# QN908XC register map
Vendor: nxp.com; File version: 1.0
CPU: CM4 r0p1, little endian, no MPU, no FPU, 0x3 interrupt priority bits, 0x0 interrupts
Registers are 32-bit, read-write, reset 0x0 unless marked. A register's access mark holds for its fields unless they carry their own. Offsets are from the block's base; [hi:lo] are bit positions; {n}, {i} and the like mark numbered series.

## FSP
Base 0x40088000
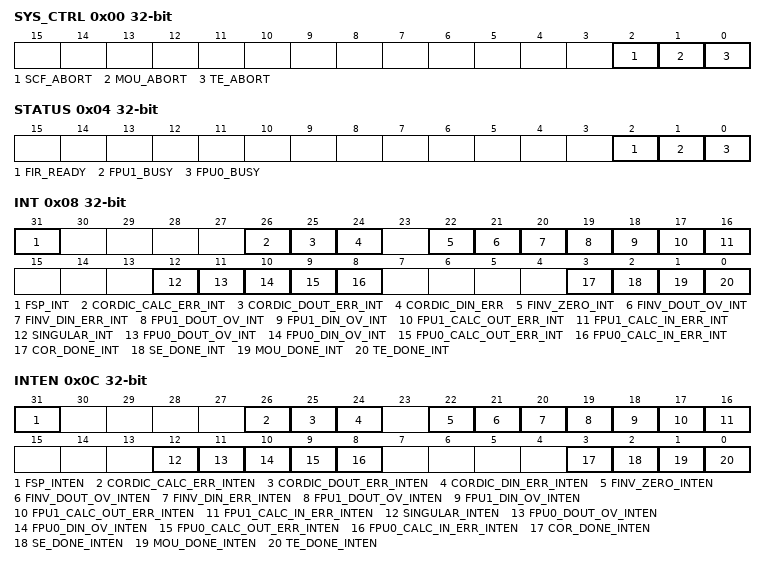
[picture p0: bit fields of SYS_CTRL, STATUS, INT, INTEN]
0x00 SYS_CTRL reset not defined — FSP system control register
  [2] SCF_ABORT wo — SE COR FIR abort write 1 to abort
  [1] MOU_ABORT wo — Matrix Operation Unit abort write 1 to abort
  [0] TE_ABORT wo — Transform Engine abort write 1 to abort
0x04 STATUS ro — FSP status register
  [2] FIR_READY — FIR output buffer is not empty which is valid for read
  [1] FPU1_BUSY — TE MOU is in processing busy
  [0] FPU0_BUSY — SE COR FIR is in processing busy
0x08 INT — FSP interrupt register
  [31] FSP_INT ro — Or signal of all FSP function interrupt in this register
  [26] CORDIC_CALC_ERR_INT write-1-clears — CORDIC calculation error interrupt
  [25] CORDIC_DOUT_ERR_INT write-1-clears — CORDIC output data error interrupt
  [24] CORDIC_DIN_ERR write-1-clears — CORDIC input data error interrupt
  [22] FINV_ZERO_INT write-1-clears — FINV input data is zero
  [21] FINV_DOUT_OV_INT write-1-clears — FINV output data overflow
  [20] FINV_DIN_ERR_INT write-1-clears — FINV input data is inf or nan
  [19] FPU1_DOUT_OV_INT write-1-clears — MOU TE output data overflow interrupt
  [18] FPU1_DIN_OV_INT write-1-clears — MOU TE input data overflow interrupt
  [17] FPU1_CALC_OUT_ERR_INT write-1-clears — MOU TE calculation output data error interrupt
  [16] FPU1_CALC_IN_ERR_INT write-1-clears — MOU TE calculation input data error interrupt
  [12] SINGULAR_INT write-1-clears — MOU singular interrupt
  [11] FPU0_DOUT_OV_INT write-1-clears — SE COR FIR output data overflow interrupt
  [10] FPU0_DIN_OV_INT write-1-clears — SE COR FIR input data overflow interrupt (always 0)
  [9] FPU0_CALC_OUT_ERR_INT write-1-clears — SE COR FIR calculation output data error interrupt
  [8] FPU0_CALC_IN_ERR_INT write-1-clears — SE COR FIR calculation input data error interrupt
  [3] COR_DONE_INT write-1-clears — Correlation done interrupt
  [2] SE_DONE_INT write-1-clears — Statistic engine done interrupt
  [1] MOU_DONE_INT write-1-clears — Matrix operation unit done interrupt
  [0] TE_DONE_INT write-1-clears — Transform engine done interrupt
0x0C INTEN — FSP interrupt enable register
  [31] FSP_INTEN — Or signal of all FSP function interrupt in this register enable
  [26] CORDIC_CALC_ERR_INTEN — CORDIC calculation error interrupt enable
  [25] CORDIC_DOUT_ERR_INTEN — CORDIC output data error interrupt enable
  [24] CORDIC_DIN_ERR_INTEN — CORDIC input data error interrupt enable
  [22] FINV_ZERO_INTEN — FINV input is zero interrupt enable
  [21] FINV_DOUT_OV_INTEN — FINV data output overflow interrupt enable
  [20] FINV_DIN_ERR_INTEN — FINV data input is inf or nan interrupt enable
  [19] FPU1_DOUT_OV_INTEN — MOU TE output data overflow interrupt enable
  [18] FPU1_DIN_OV_INTEN — MOU TE input data overflow interrupt enable
  [17] FPU1_CALC_OUT_ERR_INTEN — MOU TE calculation output data error interrupt enable
  [16] FPU1_CALC_IN_ERR_INTEN — MOU TE calculation input data error interrupt enable
  [12] SINGULAR_INTEN — MOU singular interrupt enable
  [11] FPU0_DOUT_OV_INTEN — SE COR FIR output data overflow interrupt enable
  [10] FPU0_DIN_OV_INTEN — SE COR FIR input data overflow interrupt enable
  [9] FPU0_CALC_OUT_ERR_INTEN — SE COR FIR calculation output data error interrupt enable
  [8] FPU0_CALC_IN_ERR_INTEN — SE COR FIR calculation input data error interrupt enable
  [3] COR_DONE_INTEN — Correlation done interrupt enable
  [2] SE_DONE_INTEN — Statistic engine done interrupt enable
  [1] MOU_DONE_INTEN — Matrix operation unit done interrupt enable
  [0] TE_DONE_INTEN — Transform engine done interrupt enable
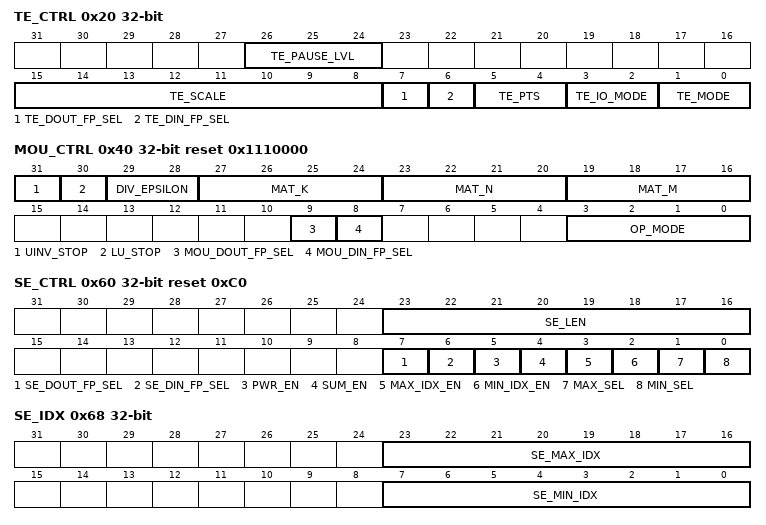
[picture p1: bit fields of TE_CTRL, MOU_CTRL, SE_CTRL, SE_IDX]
0x20 TE_CTRL — transmit engine control register
  [26:24] TE_PAUSE_LVL — Transfer Engine stop level for debug use only.
  [15:8] TE_SCALE
  [7] TE_DOUT_FP_SEL — TE output data format select
    0=FIX; 1=FLT (float)
  [6] TE_DIN_FP_SEL — TE input data format select
    0=FIX; 1=FLT (float)
  [5:4] TE_PTS — TE compute point
    0=TE64PTS (64 points); 1=TE128PTS (128 points); 2=TE256PTS (256 points)
  [3:2] TE_IO_MODE — TE input & output mode select
    0=TE_RICO (real input, complex output); 1=TE_CICO (complex input, complex output); 2=TE_RIRO (real input, real output)
  [1:0] TE_MODE — TE compute mode
    0=TE_FFT (FFT); 1=TE_IFFT (IFFT); 2=TE_DCT (DCT); 3=TE_IDCT (IDCT)
0x24 TE_SRC_BASE — transfer engine source data memory base register
  [16:0] TE_SRC_BASE — TE source data memory base address
0x28 TE_DST_BASE — transfer engine destination data memory base register
  [16:0] TE_DST_BASE — TE destination data memory base address
0x40 MOU_CTRL reset 0x1110000 — matrix operation unit control register
  [31] UINV_STOP — stop at U-Matrix inverse
  [30] LU_STOP — Stop at LU
  [29:28] DIV_EPSILON — When the data exponent is small than DIV_EPSILON the inverse operation will output a error signal.
  [27:24] MAT_K — MOU Matrix row only valid when matrix mult operation
  [23:20] MAT_N — MOU Matrix row only valid when matrix's column is not equal to row
  [19:16] MAT_M — MOU Matrix column
  [9] MOU_DOUT_FP_SEL — MOU data output format select
    0=MOU_FLT (float); 1=MOU_FIX (fix)
  [8] MOU_DIN_FP_SEL — MOU data input format select
    0=MOU_FLT (float); 1=MOU_FIX (fix)
  [3:0] OP_MODE — MOU operation mode
    0=INV (inversion); 1=MULT (matrix multiply); 2=TRANS (transposition); 3=LINEAR (linear operation); 4=DOTMULT (dot multiply)
0x44 MA_SRC_BASE — matrix A source data memory base register
  [16:0] MA_SRC_BASE — Matrix A source data memory base address
0x48 MB_SRC_BASE — matrix B source data memory base register
  [16:0] MB_SRC_BASE — Matrix B source data memory base address
0x4C MO_DST_BASE — matrix output data memory base register
  [16:0] MO_DST_BASE — Matrix Operation Unit output data destination memory base address
0x50 MOU_SCALEA — scale coefficient A register
  [31:0] MOU_SCALEA — MOU scale coefficient A
0x54 MOU_SCALEB — scale coefficient B register
  [31:0] MOU_SCALEB — MOU scale coefficient B
0x60 SE_CTRL reset 0xC0 — stastic engine control register
  [23:16] SE_LEN — Statistic engine length
  [7] SE_DOUT_FP_SEL — SE data output format select
  [6] SE_DIN_FP_SEL — SE data input format select
    0=SE_FLT (float); 1=SE_FIX (fix)
  [5] PWR_EN — Power calculation enable
  [4] SUM_EN — Summary calculation enable
  [3] MAX_IDX_EN — Maximum value index calculation enable
  [2] MIN_IDX_EN — Minimum value index calculation enable
  [1] MAX_SEL — Maximum value selection0 the first one1 the last one
  [0] MIN_SEL — Minimum value selection
    0=FIRST_ONE; 1=LAST_ONE
0x64 SE_SRC_BASE — statistic engine source data base register
  [16:0] SE_SRC_BASE — Statistic engine source data base address
0x68 SE_IDX ro — max or min data index register
  [23:16] SE_MAX_IDX — Maximum data index of an array
  [7:0] SE_MIN_IDX — Minimum data index of an array
0x6C SE_SUM ro — array summary result register
  [31:0] SE_SUM — Summary of an array
0x70 SE_PWR ro — array power result register
  [31:0] SE_PWR — Power value of an array
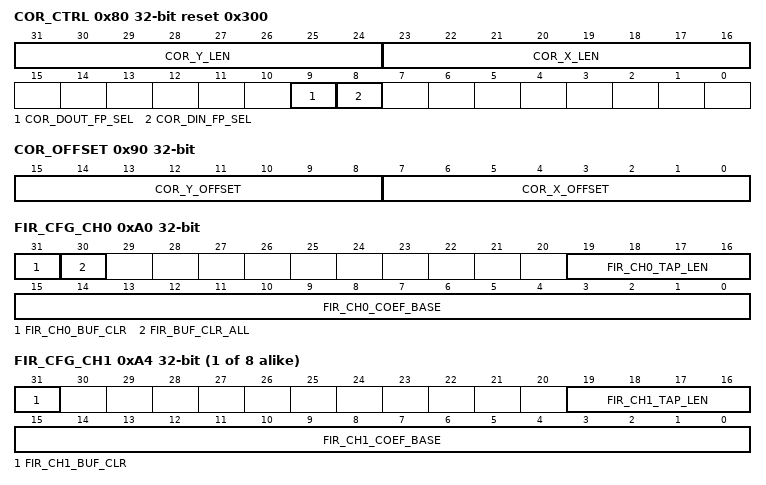
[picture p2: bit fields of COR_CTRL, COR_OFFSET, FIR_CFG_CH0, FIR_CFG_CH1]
0x80 COR_CTRL reset 0x300 — correlation control register
  [31:24] COR_Y_LEN — The length of Y sequence to be Correlator 0-255
  [23:16] COR_X_LEN — The length of X sequence to be Correlator 0-255
  [9] COR_DOUT_FP_SEL — COR output data format select
  [8] COR_DIN_FP_SEL — COR input data format select
    0=COR_FLT (float); 1=COR_FIX (fix)
0x84 CX_SRC_BASE — correlation x sequence base register
  [16:0] COR_X_ADDR — The base address of X sequence to be Correlator
0x88 CY_SRC_BASE — correlation y sequence base register
  [16:0] COR_Y_ADDR — The base address of Y sequence to be Correlator
0x8C CO_DST_BASE — correlation output sequence base register
  [16:0] COR_DST_BASE — correlation output data destination address base
0x90 COR_OFFSET — correlation offset register
  [15:8] COR_Y_OFFSET — COR input Y SEQ offset 0-255
  [7:0] COR_X_OFFSET — COR input X SEQ offset 0-255
0xA0 FIR_CFG_CH0 (reset mask 0xFFFFF) — FIR channel 0 configuration register
  [31] FIR_CH0_BUF_CLR wo — FIR channel 0 buffer clear
  [30] FIR_BUF_CLR_ALL wo — clear all FIR buffer
  [19:16] FIR_CH0_TAP_LEN — FIR channel 0 tap length the register value equals to real tap length minus 1.
  [15:0] FIR_CH0_COEF_BASE — FIR channel 0 coefficient base address
{0xA0+4i} FIR_CFG_CH{i} (reset mask 0xFFFFF) (i=1..8) — FIR channel {i} configuration register
  [31] FIR_CH{i}_BUF_CLR wo — FIR channel {i} buffer clear
  [19:16] FIR_CH{i}_TAP_LEN — FIR channel {i} tap length
  [15:0] FIR_CH{i}_COEF_BASE — FIR channel {i} coefficient base address
0xD0 FIR_DAT0_FX — FIR channel 0 fix point data input & output register
  [31:0] FIR_DAT0_FX — FIR channel 0 fix data
{0xD0+4i} FIR_DAT{i}_FX (i=1..8) — FIR channel {i} fix point data input & output register
  [31:0] FIR_DAT{i}_FX — FIR channel{i} fix data
0x100 FIR_DAT0_FL — FIR channel 0 float point data input & output register
  [31:0] FIR_DAT0_FL — FIR channel 0 float data
{0x100+4i} FIR_DAT{i}_FL (i=1..8) — FIR channel {i} float point data input & output register
  [31:0] FIR_DAT{i}_FL — FIR channel{i} float data
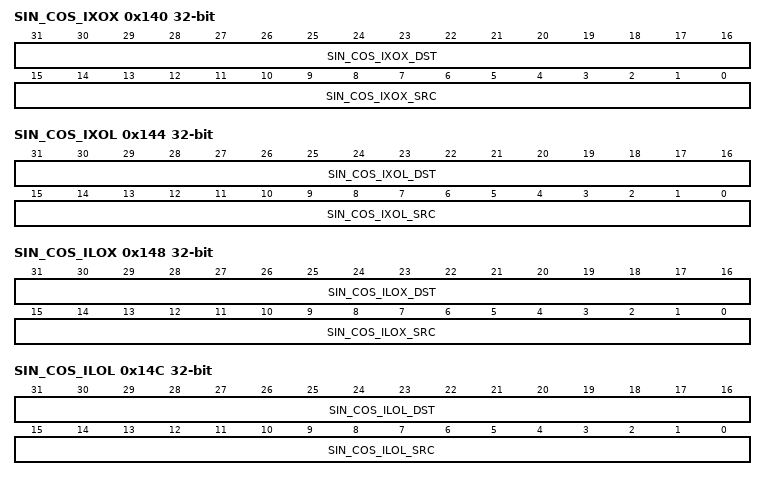
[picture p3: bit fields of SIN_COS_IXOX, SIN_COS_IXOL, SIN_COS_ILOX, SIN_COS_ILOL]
0x140 SIN_COS_IXOX wo reset not defined — sin & cos input fix output fix mode data address register
  [31:16] SIN_COS_IXOX_DST — SIN_COS output data destination address. Input fix output fix.
  [15:0] SIN_COS_IXOX_SRC — SIN_COS input data source address. Input fix output fix
0x144 SIN_COS_IXOL wo reset not defined — sin & cos input fix output float mode data address register
  [31:16] SIN_COS_IXOL_DST — SIN_COS output data destination word address. Input fix output float.
  [15:0] SIN_COS_IXOL_SRC — SIN_COS input data source word address. Input fix output float
0x148 SIN_COS_ILOX wo reset not defined — sin & cos input float output fix mode data address register
  [31:16] SIN_COS_ILOX_DST — SIN_COS output data destination word address. Input float output fix.
  [15:0] SIN_COS_ILOX_SRC — SIN_COS input data source word address. Input float output fix
0x14C SIN_COS_ILOL wo reset not defined — sin & cos input float output float mode data address register
  [31:16] SIN_COS_ILOL_DST — SIN_COS output data destination word address. Input float output float
  [15:0] SIN_COS_ILOL_SRC — SIN_COS input data source word address. Input float output float
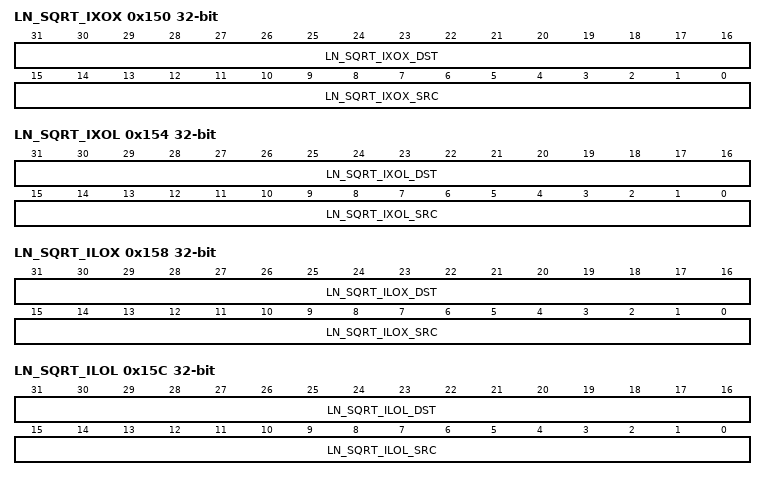
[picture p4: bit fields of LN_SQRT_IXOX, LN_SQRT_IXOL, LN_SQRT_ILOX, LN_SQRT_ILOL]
0x150 LN_SQRT_IXOX wo reset not defined — LN & sqrt input fix output fix mode data address register
  [31:16] LN_SQRT_IXOX_DST — LN_SQRT output data destination word address. Input fix output fix.
  [15:0] LN_SQRT_IXOX_SRC — LN_SQRT input data source word address. Input fix output fix
0x154 LN_SQRT_IXOL wo reset not defined — LN & sqrt input fix output float mode data address register
  [31:16] LN_SQRT_IXOL_DST — LN_SQRT output data destination word address. Input fix output float.
  [15:0] LN_SQRT_IXOL_SRC — LN_SQRT input data source word address. Input fix output float
0x158 LN_SQRT_ILOX wo reset not defined — LN & sqrt input float output fix mode data address register
  [31:16] LN_SQRT_ILOX_DST — LN_SQRT output data destination word address. Input float output fix.
  [15:0] LN_SQRT_ILOX_SRC — LN_SQRT input data source word address. Input float output fix
0x15C LN_SQRT_ILOL wo reset not defined — LN & sqrt input float output float mode data address register
  [31:16] LN_SQRT_ILOL_DST — LN_SQRT output data destination word address. Input float output float
  [15:0] LN_SQRT_ILOL_SRC — LN_SQRT input data source word address. Input float output float
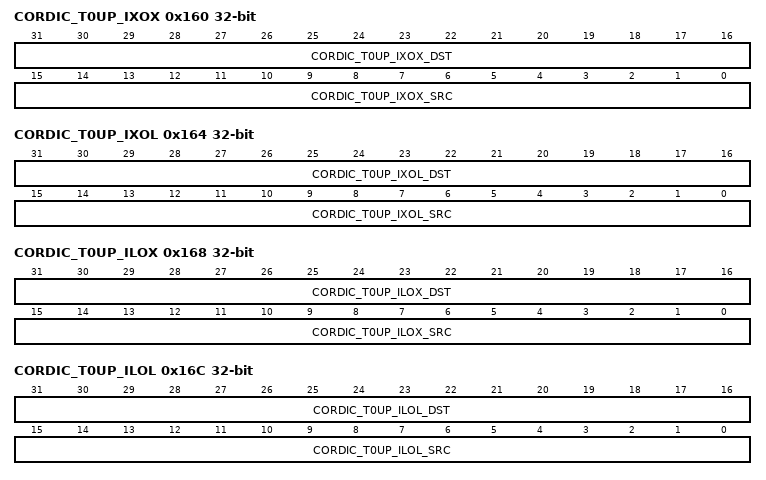
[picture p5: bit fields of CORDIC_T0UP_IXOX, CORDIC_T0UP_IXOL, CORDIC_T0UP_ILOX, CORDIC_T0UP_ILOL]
0x160 CORDIC_T0UP_IXOX wo reset not defined — native cordic input fix output fix, t=0, u=1 mode data address register
  [31:16] CORDIC_T0UP_IXOX_DST — CORDIC_T0UP_IXOX output data destination word address. X is saved at here Y is saved at word address CORDIC_T0UP_IXOX_DST+1. Input fix output fix
  [15:0] CORDIC_T0UP_IXOX_SRC — CORDIC_T0UP_IXOX input data source word address. Input fix output fix
0x164 CORDIC_T0UP_IXOL wo reset not defined — native cordic input fix output float, t=0, u=1 mode data address register
  [31:16] CORDIC_T0UP_IXOL_DST — CORDIC_T0UP_IXOL output data destination word address. X is saved at here Y is saved at word address CORDIC_T0UP_IXOL_DST+1. Input fix output float
  [15:0] CORDIC_T0UP_IXOL_SRC — CORDIC_T0UP_IXOL input data source word address. Input fix output float
0x168 CORDIC_T0UP_ILOX wo reset not defined — native cordic input float output fix, t=0, u=1 mode data address register
  [31:16] CORDIC_T0UP_ILOX_DST — CORDIC_T0UP_ILOX output data destination word address. X is saved at here Y is saved at word address CORDIC_T0UP_ILOX_DST+1. Input float output fix
  [15:0] CORDIC_T0UP_ILOX_SRC — CORDIC_T0UP_ILOX input data source word address. Input float output fix
0x16C CORDIC_T0UP_ILOL wo reset not defined — native cordic input float output float, t=0, u=1 mode data address register
  [31:16] CORDIC_T0UP_ILOL_DST — CORDIC_T0UN_ILOL output data destination word address. X is saved at here Y is saved at word address CORDIC_T0UN_ILOL_DST+1. Input float output float
  [15:0] CORDIC_T0UP_ILOL_SRC — CORDIC_T0UN_ILOL input data source word address. Input float output float
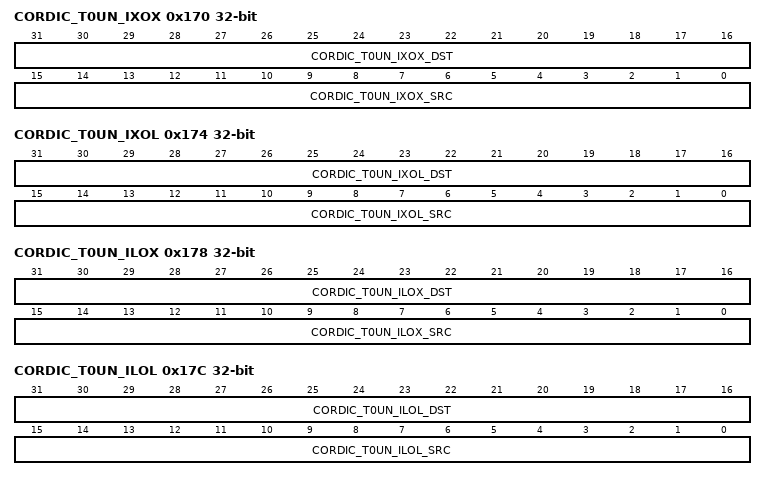
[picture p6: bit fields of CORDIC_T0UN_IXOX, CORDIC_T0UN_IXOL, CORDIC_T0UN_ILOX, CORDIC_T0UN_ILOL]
0x170 CORDIC_T0UN_IXOX wo reset not defined — native cordic input fix output fix, t=0, u=-1 mode data address register
  [31:16] CORDIC_T0UN_IXOX_DST — CORDIC_T0UN_IXOX output data destination word address. X is saved at here Y is saved at word address CORDIC_T0UN_IXOX_DST+1. Input fix output fix
  [15:0] CORDIC_T0UN_IXOX_SRC — CORDIC_T0UN_IXOX input data source word address. Input fix output fix
0x174 CORDIC_T0UN_IXOL wo reset not defined — native cordic input fix output float, t=0, u=-1 mode data address register
  [31:16] CORDIC_T0UN_IXOL_DST — CORDIC_T0UN_IXOL output data destination word address. X is saved at here Y is saved at word address CORDIC_T0UN_IXOL_DST+1. Input fix output float
  [15:0] CORDIC_T0UN_IXOL_SRC — CORDIC_T0UN_IXOL input data source word address. Input fix output float
0x178 CORDIC_T0UN_ILOX wo reset not defined — native cordic input float output fix, t=0, u=-1 mode data address register
  [31:16] CORDIC_T0UN_ILOX_DST — CORDIC_T0UN_ILOX output data destination word address. X is saved at here Y is saved at word address CORDIC_T0UN_ILOX_DST+1. Input float output fix
  [15:0] CORDIC_T0UN_ILOX_SRC — CORDIC_T0UN_ILOX input data source word address. Input float output fix
0x17C CORDIC_T0UN_ILOL wo reset not defined — native cordic input float output float, t=0, u=-1 mode data address register
  [31:16] CORDIC_T0UN_ILOL_DST — CORDIC_T0UN_ILOL output data destination word address. X is saved at here Y is saved at word address CORDIC_T0UN_ILOL_DST+1. Input float output float
  [15:0] CORDIC_T0UN_ILOL_SRC — CORDIC_T0UN_ILOL input data source word address. Input float output float
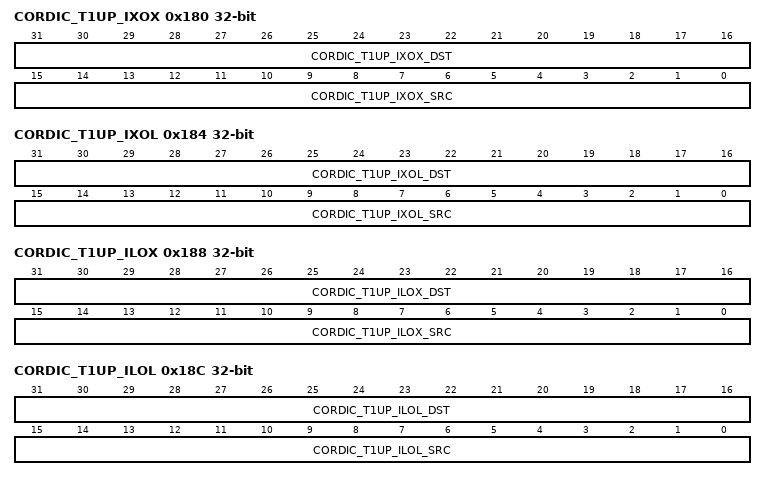
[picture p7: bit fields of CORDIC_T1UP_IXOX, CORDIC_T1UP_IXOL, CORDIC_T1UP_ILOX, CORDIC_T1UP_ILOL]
0x180 CORDIC_T1UP_IXOX wo reset not defined — native cordic input fix output fix, t=1, u=1 mode data address register
  [31:16] CORDIC_T1UP_IXOX_DST — CORDIC_T1UP_IXOX output data destination word address. X is saved at here Z is saved at word address CORDIC_T1UP_IXOX_DST+1. Input fix output fix
  [15:0] CORDIC_T1UP_IXOX_SRC — CORDIC_T1UP_IXOX input data source word address. Input fix output fix
0x184 CORDIC_T1UP_IXOL wo reset not defined — native cordic input fix output float, t=1, u=1 mode data address register
  [31:16] CORDIC_T1UP_IXOL_DST — CORDIC_T1UP_IXOL output data destination word address. X is saved at here Z is saved at word address CORDIC_T1UP_IXOL_DST+1. Input fix output float
  [15:0] CORDIC_T1UP_IXOL_SRC — CORDIC_T1UP_IXOL input data source word address. Input fix output float
0x188 CORDIC_T1UP_ILOX wo reset not defined — native cordic input float output fix, t=1, u=1 mode data address register
  [31:16] CORDIC_T1UP_ILOX_DST — CORDIC_T1UP_ILOX output data destination word address. X is saved at here Z is saved at word address CORDIC_T1UP_ILOX_DST+1. Input float output fix
  [15:0] CORDIC_T1UP_ILOX_SRC — CORDIC_T1UP_ILOX input data source word address. Input float output fix
0x18C CORDIC_T1UP_ILOL wo reset not defined — native cordic input float output float, t=1, u=1 mode data address register
  [31:16] CORDIC_T1UP_ILOL_DST — CORDIC_T1UP_ILOL output data destination word address. X is saved at here Z is saved at word address CORDIC_T1UP_ILOL_DST+1. Input float output float
  [15:0] CORDIC_T1UP_ILOL_SRC — CORDIC_T1UP_ILOL input data source word address. Input float output float
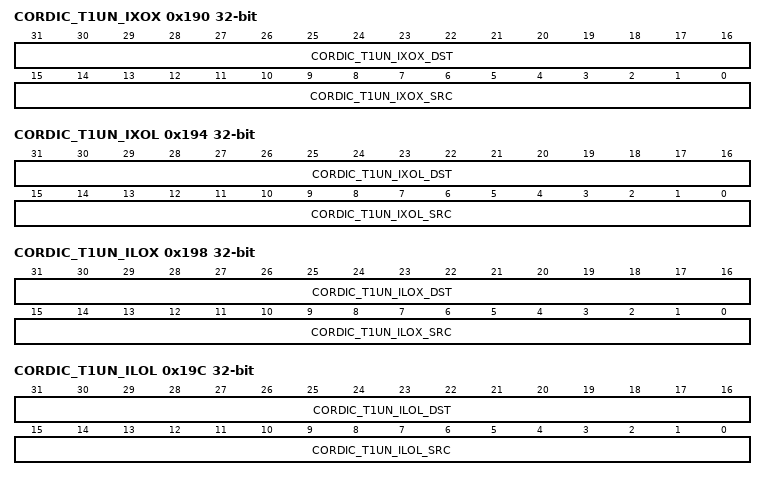
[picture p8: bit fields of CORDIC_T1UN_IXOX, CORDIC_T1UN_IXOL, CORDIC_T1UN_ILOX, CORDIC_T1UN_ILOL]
0x190 CORDIC_T1UN_IXOX wo reset not defined — native cordic input fix output fix, t=1, u=-1 mode data address register
  [31:16] CORDIC_T1UN_IXOX_DST — CORDIC_T1UN_IXOX output data destination word address. X is saved at here Z is saved at word address CORDIC_T1UN_IXOX_DST+1. Input fix output fix
  [15:0] CORDIC_T1UN_IXOX_SRC — CORDIC_T1UN_IXOX input data source word address. Input fix output fix
0x194 CORDIC_T1UN_IXOL wo reset not defined — native cordic input fix output float, t=1, u=-1 mode data address register
  [31:16] CORDIC_T1UN_IXOL_DST — CORDIC_T1UN_IXOL output data destination word address. X is saved at here Z is saved at word address CORDIC_T1UN_IXOL_DST+1. Input fix output float
  [15:0] CORDIC_T1UN_IXOL_SRC — CORDIC_T1UN_IXOL input data source word address. Input fix output float
0x198 CORDIC_T1UN_ILOX wo reset not defined — native cordic input float output fix, t=1, u=-1 mode data address register
  [31:16] CORDIC_T1UN_ILOX_DST — CORDIC_T1UN_ILOX output data destination word address. X is saved at here Z is saved at word address CORDIC_T1UN_ILOX_DST+1. Input float output fix
  [15:0] CORDIC_T1UN_ILOX_SRC — CORDIC_T1UN_ILOX input data source word address. Input float output fix
0x19C CORDIC_T1UN_ILOL wo reset not defined — native cordic input float output float, t=1, u=-1 mode data address register
  [31:16] CORDIC_T1UN_ILOL_DST — CORDIC_T1UN_ILOL output data destination word address. X is saved at here Z is saved at word address CORDIC_T1UN_ILOL_DST+1. Input float output float
  [15:0] CORDIC_T1UN_ILOL_SRC — CORDIC_T1UN_ILOL input data source word address. Input float output float
